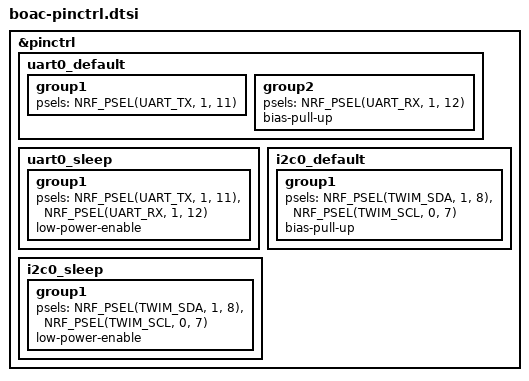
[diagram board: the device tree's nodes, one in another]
/*
 * Copyright (c) 2025 Reto Schneider
 *
 * SPDX-License-Identifier: Apache-2.0
 */

&pinctrl {
	uart0_default: uart0_default {
		group1 {
			psels = <NRF_PSEL(UART_TX, 1, 11)>;
		};
		group2 {
			psels = <NRF_PSEL(UART_RX, 1, 12)>;
			bias-pull-up;
		};
	};

	uart0_sleep: uart0_sleep {
		group1 {
			psels = <NRF_PSEL(UART_TX, 1, 11)>,
				<NRF_PSEL(UART_RX, 1, 12)>;
			low-power-enable;
		};
	};

	i2c0_default: i2c0_default {
		group1 {
			psels = <NRF_PSEL(TWIM_SDA, 1, 8)>,
					<NRF_PSEL(TWIM_SCL, 0, 7)>;
			bias-pull-up;
		};
	};

	i2c0_sleep: i2c0_sleep {
		group1 {
			psels = <NRF_PSEL(TWIM_SDA, 1, 8)>,
					<NRF_PSEL(TWIM_SCL, 0, 7)>;
			low-power-enable;
		};
	};
};
